# MCU_NAVSS0_PSILSS_0_UDMASS_PSILSS0_CFG_MMRS register map
Vendor: Texas Instruments
Peripheral module from a debugger description file (folder J7_AHP).
Registers are 32-bit, read-only, reset 0x0 unless marked. A register's access mark holds for its fields unless they carry their own. Offsets are as the file gives them; lines under a group give offsets from that group; [hi:lo] are bit positions; {n}, {i} and the like mark numbered series; 'fields as' and 'values as' point back to an identical list; <NAME> marks a mode.

## MCU_NAVSS0_PSILSS_0_UDMASS_PSILSS0_CFG_MMRS
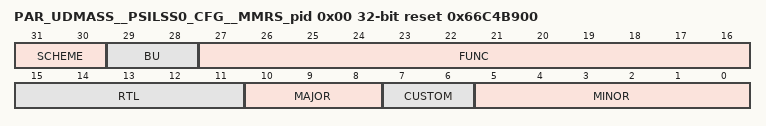
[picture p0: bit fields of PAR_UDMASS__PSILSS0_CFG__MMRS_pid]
0x00 PAR_UDMASS__PSILSS0_CFG__MMRS_pid reset 0x66C4B900
  [31:30] SCHEME — PID register scheme
  [29:28] BU — Business Unit: 10 = Processors
  [27:16] FUNC — Module ID
  [15:11] RTL — RTL revision. Will vary depending on release.
  [10:8] MAJOR — Major revision
  [7:6] CUSTOM
  [5:0] MINOR — Minor revision
0x04 PAR_UDMASS__PSILSS0_CFG__MMRS_config reset 0x15
  [15:0] ENDPOINTS — Number of endpoints supported.
0x10 PAR_UDMASS__PSILSS0_CFG__MMRS_event rw reset 0xFFFF
  [15:0] EVT — The event to produce.
0x20 PAR_UDMASS__PSILSS0_CFG__MMRS_link
  [31:0] STATUS — The status of the endpoint links.
0x40 PAR_UDMASS__PSILSS0_CFG__MMRS_down access not given
  [31:0] STATUS — The down status of the endpoint links. (access R/W1TC)
